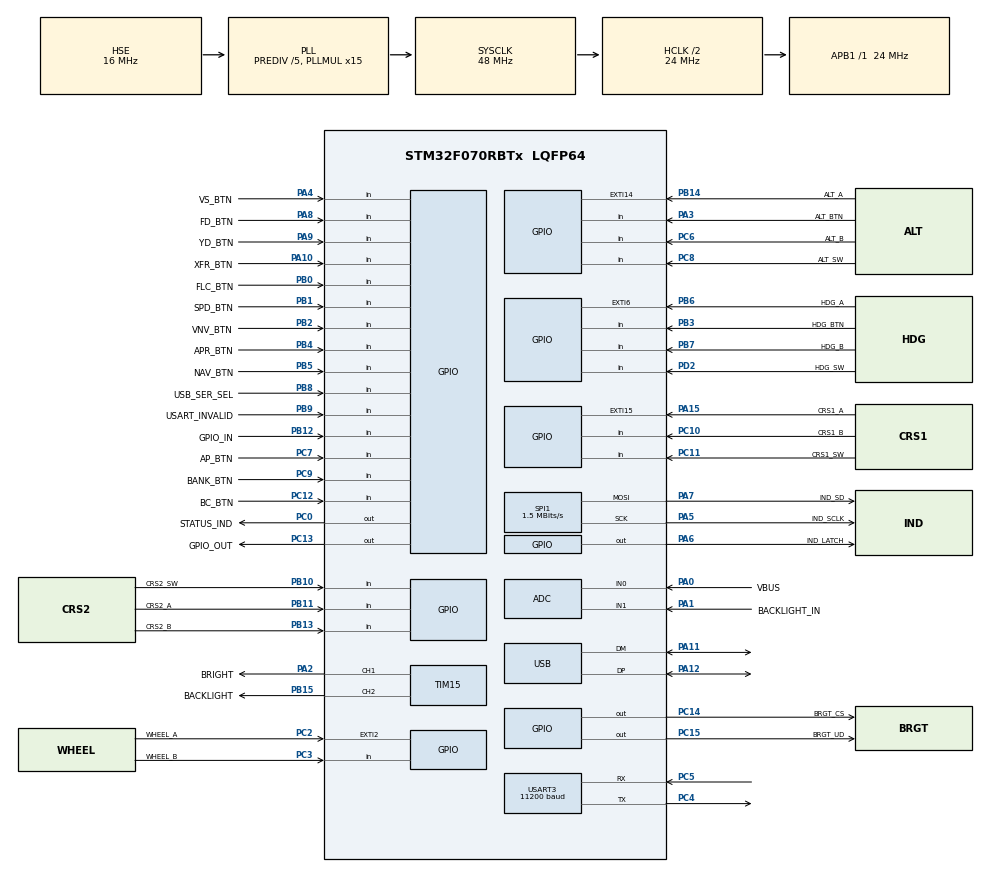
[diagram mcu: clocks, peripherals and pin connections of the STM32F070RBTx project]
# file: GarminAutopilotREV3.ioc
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Mcu.Family=STM32F0
Mcu.Name=STM32F070RBTx
Mcu.Package=LQFP64
NVIC.EXTI2_3_IRQn=true\:0\:0\:false\:false\:true\:true\:true\:true
NVIC.EXTI4_15_IRQn=true\:0\:0\:false\:false\:true\:true\:true\:true
NVIC.TIM1_BRK_UP_TRG_COM_IRQn=true\:0\:0\:false\:false\:true\:true\:true\:true
NVIC.TIM7_IRQn=true\:0\:0\:false\:false\:true\:true\:true\:true
NVIC.USART3_4_IRQn=true\:0\:0\:false\:false\:true\:true\:true\:true
NVIC.USB_IRQn=true\:0\:0\:false\:false\:true\:false\:true\:true
PA0.GPIO_Label=VBUS
PA0.Mode=IN0
PA0.Signal=ADC_IN0
PA1.GPIO_Label=BACKLIGHT_IN
PA1.Mode=IN1
PA1.Signal=ADC_IN1
PA10.GPIO_Label=XFR_BTN
PA10.Signal=GPIO_Input
PA11.Mode=Device
PA11.Signal=USB_DM
PA12.Mode=Device
PA12.Signal=USB_DP
PA13.Mode=Serial_Wire
PA13.Signal=SYS_SWDIO
PA14.Mode=Serial_Wire
PA14.Signal=SYS_SWCLK
PA15.GPIO_Label=CRS1_A
PA15.Signal=GPXTI15
PA2.GPIO_Label=BRIGHT
PA2.Signal=S_TIM15_CH1
PA3.GPIO_Label=ALT_BTN
PA3.Signal=GPIO_Input
PA4.GPIO_Label=VS_BTN
PA4.Signal=GPIO_Input
PA5.GPIO_Label=IND_SCLK
PA5.Mode=TX_Only_Simplex_Unidirect_Master
PA5.Signal=SPI1_SCK
PA6.GPIO_Label=IND_LATCH
PA6.Signal=GPIO_Output
PA7.GPIO_Label=IND_SD
PA7.Mode=TX_Only_Simplex_Unidirect_Master
PA7.Signal=SPI1_MOSI
PA8.GPIO_Label=FD_BTN
PA8.Signal=GPIO_Input
PA9.GPIO_Label=YD_BTN
PA9.Signal=GPIO_Input
PB0.GPIO_Label=FLC_BTN
PB0.Signal=GPIO_Input
PB1.GPIO_Label=SPD_BTN
PB1.Signal=GPIO_Input
PB10.GPIO_Label=CRS2_SW
PB10.Signal=GPIO_Input
PB11.GPIO_Label=CRS2_A
PB11.Signal=GPIO_Input
PB12.GPIO_Label=GPIO_IN
PB12.Signal=GPIO_Input
PB13.GPIO_Label=CRS2_B
PB13.Signal=GPIO_Input
PB14.GPIO_Label=ALT_A
PB14.Signal=GPXTI14
PB15.GPIO_Label=BACKLIGHT
PB15.Signal=S_TIM15_CH2
PB2.GPIO_Label=VNV_BTN
PB2.Signal=GPIO_Input
PB3.GPIO_Label=HDG_BTN
PB3.Signal=GPIO_Input
PB4.GPIO_Label=APR_BTN
PB4.Signal=GPIO_Input
PB5.GPIO_Label=NAV_BTN
PB5.Signal=GPIO_Input
PB6.GPIO_Label=HDG_A
PB6.Signal=GPXTI6
PB7.GPIO_Label=HDG_B
PB7.Signal=GPIO_Input
PB8.GPIO_Label=USB_SER_SEL
PB8.Signal=GPIO_Input
PB9.GPIO_Label=USART_INVALID
PB9.Signal=GPIO_Input
PC0.GPIO_Label=STATUS_IND
PC0.Signal=GPIO_Output
PC10.GPIO_Label=CRS1_B
PC10.Signal=GPIO_Input
PC11.GPIO_Label=CRS1_SW
PC11.Signal=GPIO_Input
PC12.GPIO_Label=BC_BTN
PC12.Signal=GPIO_Input
PC13.GPIO_Label=GPIO_OUT
PC13.Signal=GPIO_Output
PC14-OSC32_IN.GPIO_Label=BRGT_CS
PC14-OSC32_IN.Signal=GPIO_Output
PC15-OSC32_OUT.GPIO_Label=BRGT_UD
PC15-OSC32_OUT.Signal=GPIO_Output
PC2.GPIO_Label=WHEEL_A
PC2.Signal=GPXTI2
PC3.GPIO_Label=WHEEL_B
PC3.Signal=GPIO_Input
PC4.Mode=Asynchronous
PC4.Signal=USART3_TX
PC5.Mode=Asynchronous
PC5.Signal=USART3_RX
PC6.GPIO_Label=ALT_B
PC6.Signal=GPIO_Input
PC7.GPIO_Label=AP_BTN
PC7.Signal=GPIO_Input
PC8.GPIO_Label=ALT_SW
PC8.Signal=GPIO_Input
PC9.GPIO_Label=BANK_BTN
PC9.Signal=GPIO_Input
PD2.GPIO_Label=HDG_SW
PD2.Signal=GPIO_Input
PF0-OSC_IN.Mode=HSE-External-Oscillator
PF0-OSC_IN.Signal=RCC_OSC_IN
PF1-OSC_OUT.Mode=HSE-External-Oscillator
PF1-OSC_OUT.Signal=RCC_OSC_OUT
ProjectManager.HeapSize=0x800
ProjectManager.StackSize=0x1000
ProjectManager.TargetToolchain=STM32CubeIDE
RCC.AHBCLKDivider=RCC_SYSCLK_DIV2
RCC.AHBFreq_Value=24000000
RCC.APB1Freq_Value=24000000
RCC.APB1TimFreq_Value=24000000
RCC.HCLKFreq_Value=24000000
RCC.HSE_VALUE=16000000
RCC.PLLDivider=RCC_PREDIV_DIV5
RCC.PLLMUL=RCC_PLL_MUL15
RCC.SYSCLKFreq_VALUE=48000000
RCC.SYSCLKSource=RCC_SYSCLKSOURCE_PLLCLK
SH.S_TIM15_CH1.0=TIM15_CH1,PWM Generation1 CH1
SH.S_TIM15_CH2.0=TIM15_CH2,PWM Generation2 CH2
SPI1.BaudRatePrescaler=SPI_BAUDRATEPRESCALER_16
SPI1.CalculateBaudRate=1.5 MBits/s
SPI1.DataSize=SPI_DATASIZE_8BIT
SPI1.Direction=SPI_DIRECTION_2LINES
SPI1.Mode=SPI_MODE_MASTER
SPI1.VirtualType=VM_MASTER
TIM1.AutoReloadPreload=TIM_AUTORELOAD_PRELOAD_ENABLE
TIM1.Period=42857
TIM1.Prescaler=27
TIM1.TIM_MasterOutputTrigger=TIM_TRGO_UPDATE
TIM15.AutoReloadPreload=TIM_AUTORELOAD_PRELOAD_ENABLE
TIM15.Channel-PWM\ Generation1\ CH1=TIM_CHANNEL_1
TIM15.Channel-PWM\ Generation2\ CH2=TIM_CHANNEL_2
TIM15.OCIdleState_1=TIM_OCIDLESTATE_SET
TIM15.OCPolarity_1=TIM_OCPOLARITY_LOW
TIM7.AutoReloadPreload=TIM_AUTORELOAD_PRELOAD_ENABLE
TIM7.Period=40000
TIM7.Prescaler=11
USART3.BaudRate=11200
USART3.VirtualMode-Asynchronous=VM_ASYNC
USB_DEVICE.CLASS_NAME_FS=CDC
USB_DEVICE.MANUFACTURER_STRING=DaxxnIndustries
USB_DEVICE.PID_CDC_FS=0x1111
USB_DEVICE.PRODUCT_STRING_CDC_FS=Garmin AP ComPort
USB_DEVICE.VID=0x4224
USB_DEVICE.VirtualMode=Cdc
USB_DEVICE.VirtualModeFS=Cdc_FS
VP_ADC_TempSens_Input.Mode=IN-TempSens
VP_TIM15_VS_ClockSourceINT.Mode=Internal
VP_TIM1_VS_ClockSourceINT.Mode=Internal
VP_TIM7_VS_ClockSourceINT.Mode=Enable_Timer
VP_USB_DEVICE_VS_USB_DEVICE_CDC_FS.Mode=CDC_FS
board=custom

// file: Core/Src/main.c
/* USER CODE BEGIN Header */
/**
  ******************************************************************************
  * @file           : main.c
  * @brief          : Main program body
  ******************************************************************************
  * @attention
  *
  * Copyright (c) 2024 STMicroelectronics.
  * All rights reserved.
  *
  * This software is licensed under terms that can be found in the LICENSE file
  * in the root directory of this software component.
  * If no LICENSE file comes with this software, it is provided AS-IS.
  *
  ******************************************************************************
  */
/* USER CODE END Header */
#include "main.h"
#include "usb_device.h"

ADC_HandleTypeDef hadc;

SPI_HandleTypeDef hspi1;

TIM_HandleTypeDef htim1;
TIM_HandleTypeDef htim7;
TIM_HandleTypeDef htim15;

UART_HandleTypeDef huart3;

void SystemClock_Config(void);
static void MX_GPIO_Init(void);
static void MX_SPI1_Init(void);
static void MX_TIM15_Init(void);
static void MX_USART3_UART_Init(void);
static void MX_ADC_Init(void);
static void MX_TIM1_Init(void);
static void MX_TIM7_Init(void);

/* USER CODE BEGIN 0 */
void HAL_GPIO_EXTI_Callback(uint16_t GPIO_Pin)
{
	EncInterruptCallback(GPIO_Pin);
}

void HAL_TIM_PeriodElapsedCallback(TIM_HandleTypeDef *htim)
{
	TimerElapsedCallback(htim);
}
/* USER CODE END 0 */

int main(void)
{

  /* MCU Configuration--------------------------------------------------------*/

  /* Reset of all peripherals, Initializes the Flash interface and the Systick. */
  HAL_Init();

  /* Configure the system clock */
  SystemClock_Config();

  /* Initialize all configured peripherals */
  MX_GPIO_Init();
  MX_SPI1_Init();
  MX_TIM15_Init();
  MX_USART3_UART_Init();
  MX_USB_DEVICE_Init();
  MX_ADC_Init();
  MX_TIM1_Init();
  MX_TIM7_Init();
  /* USER CODE BEGIN 2 */
  HAL_Delay(200);
  if (Init(&hadc, &hspi1, &htim15, &huart3, &htim7) != HAL_OK)
  {
	  Error_Handler();
  }
  /* USER CODE END 2 */

  /* Infinite loop */
  /* USER CODE BEGIN WHILE */
  while (1)
  {
	  Main();
    /* USER CODE END WHILE */

  }
}

void SystemClock_Config(void)
{
  RCC_OscInitTypeDef RCC_OscInitStruct = {0};
  RCC_ClkInitTypeDef RCC_ClkInitStruct = {0};
  RCC_PeriphCLKInitTypeDef PeriphClkInit = {0};

  /** Initializes the RCC Oscillators according to the specified parameters
  * in the RCC_OscInitTypeDef structure.
  */
  RCC_OscInitStruct.OscillatorType = RCC_OSCILLATORTYPE_HSI14|RCC_OSCILLATORTYPE_HSE;
  RCC_OscInitStruct.HSEState = RCC_HSE_ON;
  RCC_OscInitStruct.HSI14State = RCC_HSI14_ON;
  RCC_OscInitStruct.HSI14CalibrationValue = 16;
  RCC_OscInitStruct.PLL.PLLState = RCC_PLL_ON;
  RCC_OscInitStruct.PLL.PLLSource = RCC_PLLSOURCE_HSE;
  RCC_OscInitStruct.PLL.PLLMUL = RCC_PLL_MUL15;
  RCC_OscInitStruct.PLL.PREDIV = RCC_PREDIV_DIV5;
  if (HAL_RCC_OscConfig(&RCC_OscInitStruct) != HAL_OK)
  {
    Error_Handler();
  }

  /** Initializes the CPU, AHB and APB buses clocks
  */
  RCC_ClkInitStruct.ClockType = RCC_CLOCKTYPE_HCLK|RCC_CLOCKTYPE_SYSCLK
                              |RCC_CLOCKTYPE_PCLK1;
  RCC_ClkInitStruct.SYSCLKSource = RCC_SYSCLKSOURCE_PLLCLK;
  RCC_ClkInitStruct.AHBCLKDivider = RCC_SYSCLK_DIV2;
  RCC_ClkInitStruct.APB1CLKDivider = RCC_HCLK_DIV1;

  if (HAL_RCC_ClockConfig(&RCC_ClkInitStruct, FLASH_LATENCY_1) != HAL_OK)
  {
    Error_Handler();
  }
  PeriphClkInit.PeriphClockSelection = RCC_PERIPHCLK_USB;
  PeriphClkInit.UsbClockSelection = RCC_USBCLKSOURCE_PLL;

  if (HAL_RCCEx_PeriphCLKConfig(&PeriphClkInit) != HAL_OK)
  {
    Error_Handler();
  }
}

static void MX_ADC_Init(void)
{

  ADC_ChannelConfTypeDef sConfig = {0};

  /** Configure the global features of the ADC (Clock, Resolution, Data Alignment and number of conversion)
  */
  hadc.Instance = ADC1;
  hadc.Init.ClockPrescaler = ADC_CLOCK_ASYNC_DIV1;
  hadc.Init.Resolution = ADC_RESOLUTION_12B;
  hadc.Init.DataAlign = ADC_DATAALIGN_RIGHT;
  hadc.Init.ScanConvMode = ADC_SCAN_DIRECTION_FORWARD;
  hadc.Init.EOCSelection = ADC_EOC_SINGLE_CONV;
  hadc.Init.LowPowerAutoWait = DISABLE;
  hadc.Init.LowPowerAutoPowerOff = DISABLE;
  hadc.Init.ContinuousConvMode = DISABLE;
  hadc.Init.DiscontinuousConvMode = DISABLE;
  hadc.Init.ExternalTrigConv = ADC_SOFTWARE_START;
  hadc.Init.ExternalTrigConvEdge = ADC_EXTERNALTRIGCONVEDGE_NONE;
  hadc.Init.DMAContinuousRequests = DISABLE;
  hadc.Init.Overrun = ADC_OVR_DATA_PRESERVED;
  if (HAL_ADC_Init(&hadc) != HAL_OK)
  {
    Error_Handler();
  }

  /** Configure for the selected ADC regular channel to be converted.
  */
  sConfig.Channel = ADC_CHANNEL_0;
  sConfig.Rank = ADC_RANK_CHANNEL_NUMBER;
  sConfig.SamplingTime = ADC_SAMPLETIME_1CYCLE_5;
  if (HAL_ADC_ConfigChannel(&hadc, &sConfig) != HAL_OK)
  {
    Error_Handler();
  }

  /** Configure for the selected ADC regular channel to be converted.
  */
  sConfig.Channel = ADC_CHANNEL_1;
  if (HAL_ADC_ConfigChannel(&hadc, &sConfig) != HAL_OK)
  {
    Error_Handler();
  }

  /** Configure for the selected ADC regular channel to be converted.
  */
  sConfig.Channel = ADC_CHANNEL_TEMPSENSOR;
  if (HAL_ADC_ConfigChannel(&hadc, &sConfig) != HAL_OK)
  {
    Error_Handler();
  }

}

static void MX_SPI1_Init(void)
{

  /* SPI1 parameter configuration*/
  hspi1.Instance = SPI1;
  hspi1.Init.Mode = SPI_MODE_MASTER;
  hspi1.Init.Direction = SPI_DIRECTION_2LINES;
  hspi1.Init.DataSize = SPI_DATASIZE_8BIT;
  hspi1.Init.CLKPolarity = SPI_POLARITY_LOW;
  hspi1.Init.CLKPhase = SPI_PHASE_1EDGE;
  hspi1.Init.NSS = SPI_NSS_SOFT;
  hspi1.Init.BaudRatePrescaler = SPI_BAUDRATEPRESCALER_16;
  hspi1.Init.FirstBit = SPI_FIRSTBIT_MSB;
  hspi1.Init.TIMode = SPI_TIMODE_DISABLE;
  hspi1.Init.CRCCalculation = SPI_CRCCALCULATION_DISABLE;
  hspi1.Init.CRCPolynomial = 7;
  hspi1.Init.CRCLength = SPI_CRC_LENGTH_DATASIZE;
  hspi1.Init.NSSPMode = SPI_NSS_PULSE_ENABLE;
  if (HAL_SPI_Init(&hspi1) != HAL_OK)
  {
    Error_Handler();
  }

}

static void MX_TIM1_Init(void)
{

  TIM_ClockConfigTypeDef sClockSourceConfig = {0};
  TIM_MasterConfigTypeDef sMasterConfig = {0};

  htim1.Instance = TIM1;
  htim1.Init.Prescaler = 27;
  htim1.Init.CounterMode = TIM_COUNTERMODE_UP;
  htim1.Init.Period = 42857;
  htim1.Init.ClockDivision = TIM_CLOCKDIVISION_DIV1;
  htim1.Init.RepetitionCounter = 0;
  htim1.Init.AutoReloadPreload = TIM_AUTORELOAD_PRELOAD_ENABLE;
  if (HAL_TIM_Base_Init(&htim1) != HAL_OK)
  {
    Error_Handler();
  }
  sClockSourceConfig.ClockSource = TIM_CLOCKSOURCE_INTERNAL;
  if (HAL_TIM_ConfigClockSource(&htim1, &sClockSourceConfig) != HAL_OK)
  {
    Error_Handler();
  }
  sMasterConfig.MasterOutputTrigger = TIM_TRGO_UPDATE;
  sMasterConfig.MasterSlaveMode = TIM_MASTERSLAVEMODE_DISABLE;
  if (HAL_TIMEx_MasterConfigSynchronization(&htim1, &sMasterConfig) != HAL_OK)
  {
    Error_Handler();
  }

}

static void MX_TIM7_Init(void)
{

  htim7.Instance = TIM7;
  htim7.Init.Prescaler = 11;
  htim7.Init.CounterMode = TIM_COUNTERMODE_UP;
  htim7.Init.Period = 40000;
  htim7.Init.AutoReloadPreload = TIM_AUTORELOAD_PRELOAD_ENABLE;
  if (HAL_TIM_Base_Init(&htim7) != HAL_OK)
  {
    Error_Handler();
  }

}

static void MX_TIM15_Init(void)
{

  TIM_ClockConfigTypeDef sClockSourceConfig = {0};
  TIM_MasterConfigTypeDef sMasterConfig = {0};
  TIM_OC_InitTypeDef sConfigOC = {0};
  TIM_BreakDeadTimeConfigTypeDef sBreakDeadTimeConfig = {0};

  htim15.Instance = TIM15;
  htim15.Init.Prescaler = 0;
  htim15.Init.CounterMode = TIM_COUNTERMODE_UP;
  htim15.Init.Period = 65535;
  htim15.Init.ClockDivision = TIM_CLOCKDIVISION_DIV1;
  htim15.Init.RepetitionCounter = 0;
  htim15.Init.AutoReloadPreload = TIM_AUTORELOAD_PRELOAD_ENABLE;
  if (HAL_TIM_Base_Init(&htim15) != HAL_OK)
  {
    Error_Handler();
  }
  sClockSourceConfig.ClockSource = TIM_CLOCKSOURCE_INTERNAL;
  if (HAL_TIM_ConfigClockSource(&htim15, &sClockSourceConfig) != HAL_OK)
  {
    Error_Handler();
  }
  if (HAL_TIM_PWM_Init(&htim15) != HAL_OK)
  {
    Error_Handler();
  }
  sMasterConfig.MasterOutputTrigger = TIM_TRGO_RESET;
  sMasterConfig.MasterSlaveMode = TIM_MASTERSLAVEMODE_DISABLE;
  if (HAL_TIMEx_MasterConfigSynchronization(&htim15, &sMasterConfig) != HAL_OK)
  {
    Error_Handler();
  }
  sConfigOC.OCMode = TIM_OCMODE_PWM1;
  sConfigOC.Pulse = 0;
  sConfigOC.OCPolarity = TIM_OCPOLARITY_LOW;
  sConfigOC.OCNPolarity = TIM_OCNPOLARITY_HIGH;
  sConfigOC.OCFastMode = TIM_OCFAST_DISABLE;
  sConfigOC.OCIdleState = TIM_OCIDLESTATE_SET;
  sConfigOC.OCNIdleState = TIM_OCNIDLESTATE_RESET;
  if (HAL_TIM_PWM_ConfigChannel(&htim15, &sConfigOC, TIM_CHANNEL_1) != HAL_OK)
  {
    Error_Handler();
  }
  sConfigOC.OCPolarity = TIM_OCPOLARITY_HIGH;
  sConfigOC.OCIdleState = TIM_OCIDLESTATE_RESET;
  if (HAL_TIM_PWM_ConfigChannel(&htim15, &sConfigOC, TIM_CHANNEL_2) != HAL_OK)
  {
    Error_Handler();
  }
  sBreakDeadTimeConfig.OffStateRunMode = TIM_OSSR_DISABLE;
  sBreakDeadTimeConfig.OffStateIDLEMode = TIM_OSSI_DISABLE;
  sBreakDeadTimeConfig.LockLevel = TIM_LOCKLEVEL_OFF;
  sBreakDeadTimeConfig.DeadTime = 0;
  sBreakDeadTimeConfig.BreakState = TIM_BREAK_DISABLE;
  sBreakDeadTimeConfig.BreakPolarity = TIM_BREAKPOLARITY_HIGH;
  sBreakDeadTimeConfig.AutomaticOutput = TIM_AUTOMATICOUTPUT_DISABLE;
  if (HAL_TIMEx_ConfigBreakDeadTime(&htim15, &sBreakDeadTimeConfig) != HAL_OK)
  {
    Error_Handler();
  }
  HAL_TIM_MspPostInit(&htim15);

}

static void MX_USART3_UART_Init(void)
{

  huart3.Instance = USART3;
  huart3.Init.BaudRate = 11200;
  huart3.Init.WordLength = UART_WORDLENGTH_8B;
  huart3.Init.StopBits = UART_STOPBITS_1;
  huart3.Init.Parity = UART_PARITY_NONE;
  huart3.Init.Mode = UART_MODE_TX_RX;
  huart3.Init.HwFlowCtl = UART_HWCONTROL_NONE;
  huart3.Init.OverSampling = UART_OVERSAMPLING_16;
  huart3.Init.OneBitSampling = UART_ONE_BIT_SAMPLE_DISABLE;
  huart3.AdvancedInit.AdvFeatureInit = UART_ADVFEATURE_NO_INIT;
  if (HAL_UART_Init(&huart3) != HAL_OK)
  {
    Error_Handler();
  }

}

static void MX_GPIO_Init(void)
{
  GPIO_InitTypeDef GPIO_InitStruct = {0};

  /* GPIO Ports Clock Enable */
  __HAL_RCC_GPIOC_CLK_ENABLE();
  __HAL_RCC_GPIOF_CLK_ENABLE();
  __HAL_RCC_GPIOA_CLK_ENABLE();
  __HAL_RCC_GPIOB_CLK_ENABLE();
  __HAL_RCC_GPIOD_CLK_ENABLE();

  /*Configure GPIO pin Output Level */
  HAL_GPIO_WritePin(GPIOC, GPIO_OUT_Pin|BRGT_CS_Pin|BRGT_UD_Pin|STATUS_IND_Pin, GPIO_PIN_RESET);

  /*Configure GPIO pin Output Level */
  HAL_GPIO_WritePin(IND_LATCH_GPIO_Port, IND_LATCH_Pin, GPIO_PIN_RESET);

  /*Configure GPIO pins : GPIO_OUT_Pin BRGT_CS_Pin BRGT_UD_Pin STATUS_IND_Pin */
  GPIO_InitStruct.Pin = GPIO_OUT_Pin|BRGT_CS_Pin|BRGT_UD_Pin|STATUS_IND_Pin;
  GPIO_InitStruct.Mode = GPIO_MODE_OUTPUT_PP;
  GPIO_InitStruct.Pull = GPIO_NOPULL;
  GPIO_InitStruct.Speed = GPIO_SPEED_FREQ_LOW;
  HAL_GPIO_Init(GPIOC, &GPIO_InitStruct);

  /*Configure GPIO pin : WHEEL_A_Pin */
  GPIO_InitStruct.Pin = WHEEL_A_Pin;
  GPIO_InitStruct.Mode = GPIO_MODE_IT_RISING;
  GPIO_InitStruct.Pull = GPIO_NOPULL;
  HAL_GPIO_Init(WHEEL_A_GPIO_Port, &GPIO_InitStruct);

  /*Configure GPIO pins : WHEEL_B_Pin ALT_B_Pin AP_BTN_Pin ALT_SW_Pin
                           BANK_BTN_Pin CRS1_B_Pin CRS1_SW_Pin BC_BTN_Pin */
  GPIO_InitStruct.Pin = WHEEL_B_Pin|ALT_B_Pin|AP_BTN_Pin|ALT_SW_Pin
                          |BANK_BTN_Pin|CRS1_B_Pin|CRS1_SW_Pin|BC_BTN_Pin;
  GPIO_InitStruct.Mode = GPIO_MODE_INPUT;
  GPIO_InitStruct.Pull = GPIO_NOPULL;
  HAL_GPIO_Init(GPIOC, &GPIO_InitStruct);

  /*Configure GPIO pins : ALT_BTN_Pin VS_BTN_Pin FD_BTN_Pin YD_BTN_Pin
                           XFR_BTN_Pin */
  GPIO_InitStruct.Pin = ALT_BTN_Pin|VS_BTN_Pin|FD_BTN_Pin|YD_BTN_Pin
                          |XFR_BTN_Pin;
  GPIO_InitStruct.Mode = GPIO_MODE_INPUT;
  GPIO_InitStruct.Pull = GPIO_NOPULL;
  HAL_GPIO_Init(GPIOA, &GPIO_InitStruct);

  /*Configure GPIO pin : IND_LATCH_Pin */
  GPIO_InitStruct.Pin = IND_LATCH_Pin;
  GPIO_InitStruct.Mode = GPIO_MODE_OUTPUT_PP;
  GPIO_InitStruct.Pull = GPIO_NOPULL;
  GPIO_InitStruct.Speed = GPIO_SPEED_FREQ_LOW;
  HAL_GPIO_Init(IND_LATCH_GPIO_Port, &GPIO_InitStruct);

  /*Configure GPIO pins : FLC_BTN_Pin SPD_BTN_Pin VNV_BTN_Pin CRS2_SW_Pin
                           CRS2_A_Pin GPIO_IN_Pin CRS2_B_Pin HDG_BTN_Pin
                           APR_BTN_Pin NAV_BTN_Pin HDG_B_Pin USB_SER_SEL_Pin
                           USART_INVALID_Pin */
  GPIO_InitStruct.Pin = FLC_BTN_Pin|SPD_BTN_Pin|VNV_BTN_Pin|CRS2_SW_Pin
                          |CRS2_A_Pin|GPIO_IN_Pin|CRS2_B_Pin|HDG_BTN_Pin
                          |APR_BTN_Pin|NAV_BTN_Pin|HDG_B_Pin|USB_SER_SEL_Pin
                          |USART_INVALID_Pin;
  GPIO_InitStruct.Mode = GPIO_MODE_INPUT;
  GPIO_InitStruct.Pull = GPIO_NOPULL;
  HAL_GPIO_Init(GPIOB, &GPIO_InitStruct);

  /*Configure GPIO pins : ALT_A_Pin HDG_A_Pin */
  GPIO_InitStruct.Pin = ALT_A_Pin|HDG_A_Pin;
  GPIO_InitStruct.Mode = GPIO_MODE_IT_RISING;
  GPIO_InitStruct.Pull = GPIO_NOPULL;
  HAL_GPIO_Init(GPIOB, &GPIO_InitStruct);

  /*Configure GPIO pin : CRS1_A_Pin */
  GPIO_InitStruct.Pin = CRS1_A_Pin;
  GPIO_InitStruct.Mode = GPIO_MODE_IT_RISING;
  GPIO_InitStruct.Pull = GPIO_NOPULL;
  HAL_GPIO_Init(CRS1_A_GPIO_Port, &GPIO_InitStruct);

  /*Configure GPIO pin : HDG_SW_Pin */
  GPIO_InitStruct.Pin = HDG_SW_Pin;
  GPIO_InitStruct.Mode = GPIO_MODE_INPUT;
  GPIO_InitStruct.Pull = GPIO_NOPULL;
  HAL_GPIO_Init(HDG_SW_GPIO_Port, &GPIO_InitStruct);

  /* EXTI interrupt init*/
  HAL_NVIC_SetPriority(EXTI2_3_IRQn, 0, 0);
  HAL_NVIC_EnableIRQ(EXTI2_3_IRQn);

  HAL_NVIC_SetPriority(EXTI4_15_IRQn, 0, 0);
  HAL_NVIC_EnableIRQ(EXTI4_15_IRQn);

}

void Error_Handler(void)
{
  /* USER CODE BEGIN Error_Handler_Debug */
  /* User can add his own implementation to report the HAL error return state */

	HAL_GPIO_WritePin(STATUS_IND_GPIO_Port, STATUS_IND_Pin, GPIO_PIN_SET);

  __disable_irq();
  while (1)
  {
  }
  /* USER CODE END Error_Handler_Debug */
}
